# R7FA6M1AD register map
Vendor: Renesas; Series: RA6; File version: 1.2
CPU: CM4 r0p1, little endian, MPU, FPU, VTOR, 4 interrupt priority bits
Registers are 8-bit, read-write, reset 0x0 unless marked. A register's access mark holds for its fields unless they carry their own. Offsets are from the block's base; [hi:lo] are bit positions; {n}, {i} and the like mark numbered series; 'fields as' and 'values as' point back to an identical list.

## BUS — BUS Control
Base 0x40003000
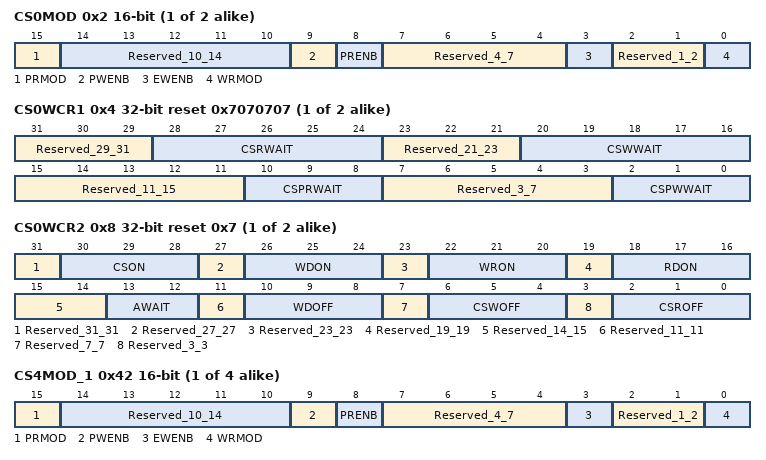
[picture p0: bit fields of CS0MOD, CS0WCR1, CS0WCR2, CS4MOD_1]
{0x2+0x10*i} CS{i}MOD (i=0..1) 16-bit — CS{i} Mode Register
  [15] PRMOD — Page Read Access Mode Select
  [14:10] Reserved_10_14 — These bits are read as 00000. The write value should be 00000.
  [9] PWENB — Page Write Access Enable
  [8] PRENB — Page Read Access Enable
  [7:4] Reserved_4_7 — These bits are read as 0000. The write value should be 0000.
  [3] EWENB — External Wait Enable
  [2:1] Reserved_1_2 — These bits are read as 00. The write value should be 00.
  [0] WRMOD — Write Access Mode Select
{0x4+0x10*i} CS{i}WCR1 (i=0..1) 32-bit reset 0x7070707 — CS{i} Wait Control Register 1
  [31:29] Reserved_29_31 — These bits are read as 000. The write value should be 000.
  [28:24] CSRWAIT — Normal Read Cycle Wait Select
  [23:21] Reserved_21_23 — These bits are read as 000. The write value should be 000.
  [20:16] CSWWAIT — Normal Write Cycle Wait Select
  [15:11] Reserved_11_15 — These bits are read as 00000. The write value should be 00000.
  [10:8] CSPRWAIT — Page Read Cycle Wait Select NOTE: The CSPRWAIT value is valid only when the PRENB bit in CSnMOD is set to 1.
  [7:3] Reserved_3_7 — These bits are read as 00000. The write value should be 00000.
  [2:0] CSPWWAIT — Page Write Cycle Wait Select NOTE: The CSPWWAIT value is valid only when the PWENB bit in CSnMOD is set to 1.
{0x8+0x10*i} CS{i}WCR2 (i=0..1) 32-bit reset 0x7 — CS{i} Wait Control Register 2
  [31] Reserved_31_31 — This bit is read as 0. The write value should be 0.
  [30:28] CSON — CS Assert Wait Select
  [27] Reserved_27_27 — This bit is read as 0. The write value should be 0.
  [26:24] WDON — Write Data Output Wait Select
  [23] Reserved_23_23 — This bit is read as 0. The write value should be 0.
  [22:20] WRON — WR Assert Wait Select
  [19] Reserved_19_19 — This bit is read as 0. The write value should be 0.
  [18:16] RDON — RD Assert Wait Select
  [15:14] Reserved_14_15 — These bits are read as 00. The write value should be 00.
  [13:12] AWAIT — Address Cycle Wait Select
  [11] Reserved_11_11 — This bit is read as 0. The write value should be 0.
  [10:8] WDOFF — Write Data Output Extension Cycle Select
  [7] Reserved_7_7 — This bit is read as 0. The write value should be 0.
  [6:4] CSWOFF — Write,Access CS Extension Cycle Select
  [3] Reserved_3_3 — This bit is read as 0. The write value should be 0.
  [2:0] CSROFF — Read,Access CS Extension Cycle Select
{0x2+0x10*i} CS{i}MOD_1 (i=4..7) 16-bit — CS{i} Mode Register
  fields as CS0MOD
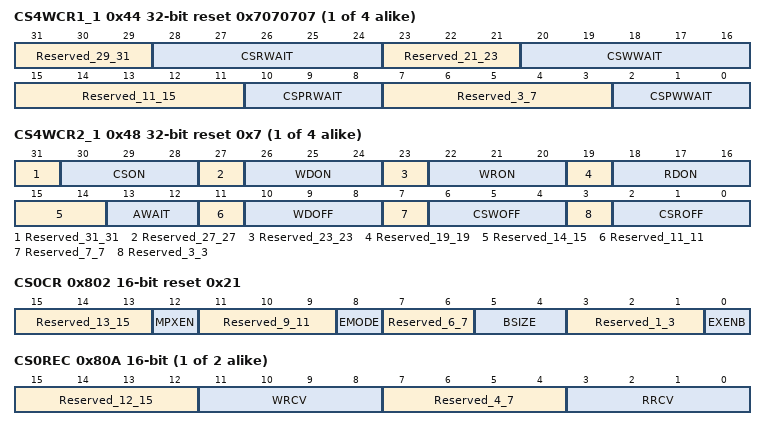
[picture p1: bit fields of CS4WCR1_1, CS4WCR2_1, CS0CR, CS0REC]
{0x4+0x10*i} CS{i}WCR1_1 (i=4..7) 32-bit reset 0x7070707 — CS{i} Wait Control Register 1
  fields as CS0WCR1
{0x8+0x10*i} CS{i}WCR2_1 (i=4..7) 32-bit reset 0x7 — CS{i} Wait Control Register 2
  fields as CS0WCR2
0x802 CS0CR 16-bit reset 0x21 — CS0 Control Register
  [15:13] Reserved_13_15 — These bits are read as 000. The write value should be 000.
  [12] MPXEN — Address/Data Multiplexed I/O Interface Select
  [11:9] Reserved_9_11 — These bits are read as 000. The write value should be 000.
  [8] EMODE — Endian Mode
  [7:6] Reserved_6_7 — These bits are read as 00. The write value should be 00.
  [5:4] BSIZE — External Bus Width Select
  [3:1] Reserved_1_3 — These bits are read as 000. The write value should be 000.
  [0] EXENB — Operation Enable
{0x80A+0x10*i} CS{i}REC (i=0..1) 16-bit — CS{i} Recovery Cycle Register
  [15:12] Reserved_12_15 — These bits are read as 0000. The write value should be 0000.
  [11:8] WRCV — Write Recovery
  [7:4] Reserved_4_7 — These bits are read as 0000. The write value should be 0000.
  [3:0] RRCV — Read Recovery
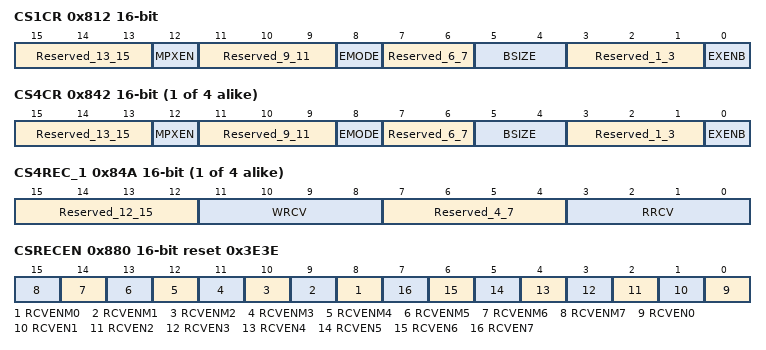
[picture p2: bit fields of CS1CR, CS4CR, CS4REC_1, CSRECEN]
0x812 CS1CR 16-bit — CS1 Control Register
  fields as CS0CR
{0x802+0x10*i} CS{i}CR (i=4..7) 16-bit — CS{i} Control Register
  fields as CS0CR
{0x80A+0x10*i} CS{i}REC_1 (i=4..7) 16-bit — CS{i} Recovery Cycle Register
  fields as CS0REC
0x880 CSRECEN 16-bit reset 0x3E3E — CS Recovery Cycle Insertion Enable Register
  [n+8] RCVENM{n} (n=0..7) — Multiplexed Bus Recovery Cycle Insertion Enable {n}
  [n] RCVEN{n} (n=0..7) — Separate Bus Recovery Cycle Insertion Enable {n}
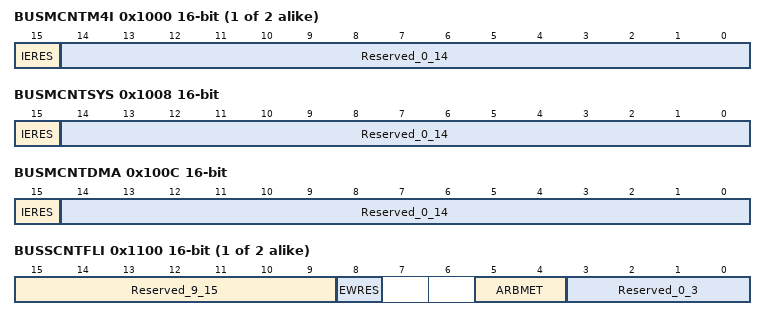
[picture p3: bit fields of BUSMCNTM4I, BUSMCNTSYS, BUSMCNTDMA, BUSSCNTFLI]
0x1000 BUSMCNT{x} (x=M4I,M4D; step 0x4) 16-bit — Master Bus Control Register {x}
  [15] IERES — Ignore Error Responses
  [14:0] Reserved_0_14 — These bits are read as 000000000000000. The write value should be 000000000000000.
0x1008 BUSMCNTSYS 16-bit — Master Bus Control Register SYS
  fields as BUSMCNT{x}
0x100C BUSMCNTDMA 16-bit — Master Bus Control Register DMA
  fields as BUSMCNT{x}
0x1100 BUSSCNT{x} (x=FLI,RAMH; step 0x4) 16-bit — Slave Bus Control Register {x}
  [15:9] Reserved_9_15 — These bits are read as 0000000. The write value should be 0000000.
  [8] EWRES — Early Write Response Whether the next write request is accepted or not until a response for the write transaction comes back.
  [5:4] ARBMET — Arbitration Method Specify the priority between groups
  [3:0] Reserved_0_3 — These bits are read as 0000. The write value should be 0000.
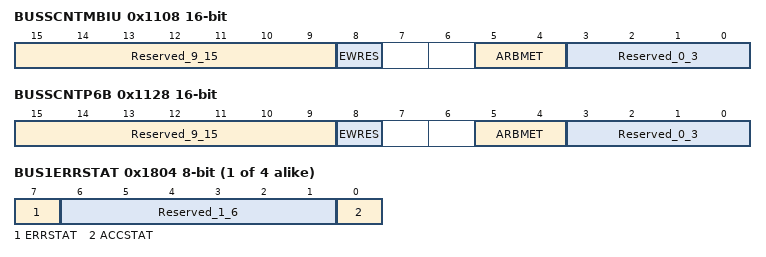
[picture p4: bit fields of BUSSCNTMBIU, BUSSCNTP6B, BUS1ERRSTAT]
0x1108 BUSSCNTMBIU 16-bit — Slave Bus Control Register MBIU
  fields as BUSSCNT{x}
0x110C BUSSCNT{x}_1 (x=RAM0,RAM1; step 0x4) 16-bit — Slave Bus Control Register {x}
  fields as BUSSCNT{x}
0x1114 BUSSCNT{x}_2 (x=P0B,P2B,P3B,P4B; step 0x4) 16-bit — Slave Bus Control Register {x}
  fields as BUSSCNT{x}
0x1128 BUSSCNTP6B 16-bit — Slave Bus Control Register P6B
  fields as BUSSCNT{x}
0x1130 BUSSCNT{x}_3 (x=FBU,EXT,EXT2; step 0x4) 16-bit — Slave Bus Control Register {x}
  fields as BUSSCNT{x}
{0x17F0+0x10*i} BUS{i}ERRADD (i=1..4) 32-bit ro reset not defined — Bus Error Address Register {i}
  [31:0] BERAD — Bus Error Address When a bus error occurs, It stores an error address.
{0x17F4+0x10*i} BUS{i}ERRSTAT (i=1..4) ro (reset mask 0xFE) — Bus Error Status Register {i}
  [7] ERRSTAT — Bus Error Status When bus error assert, error flag occurs.
  [6:1] Reserved_1_6 — These bits are read as 000000.
  [0] ACCSTAT — Error access status The status at the time of the error
